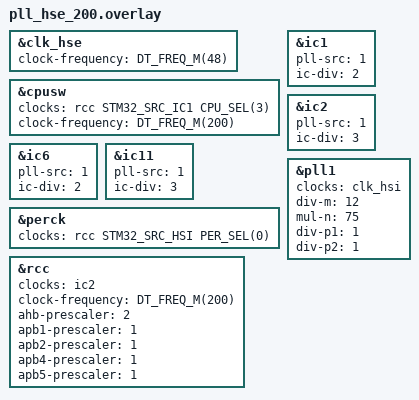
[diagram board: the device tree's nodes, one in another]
/*
 * Copyright (c) 2025 STMicroelectronics
 *
 * SPDX-License-Identifier: Apache-2.0
 */

/*
 * Warning: This overlay performs configuration from clean sheet.
 * It is assumed that it is applied after clear_clocks.overlay file.
 */

&clk_hse {
	clock-frequency = <DT_FREQ_M(48)>;
	status = "okay";
};

&cpusw {
	clocks = <&rcc STM32_SRC_IC1 CPU_SEL(3)>;
	clock-frequency = <DT_FREQ_M(200)>;
	status = "okay";
};

&ic1 {
	pll-src = <1>;
	ic-div = <2>;
	status = "okay";
};

&ic2 {
	pll-src = <1>;
	ic-div = <3>;
	status = "okay";
};

&ic6 {
	pll-src = <1>;
	ic-div = <2>;
	status = "okay";
};

&ic11 {
	pll-src = <1>;
	ic-div = <3>;
	status = "okay";
};

&perck {
	clocks = <&rcc STM32_SRC_HSI PER_SEL(0)>;
	status = "okay";
};

&pll1 {
	clocks = <&clk_hsi>;
	div-m = <12>;
	mul-n = <75>;
	div-p1 = <1>;
	div-p2 = <1>;
	status = "okay";
};

&rcc {
	/* ic2, ic6 & ic11 must all be enabled to set ic2 as SYSCLK */
	clocks = <&ic2>;
	clock-frequency = <DT_FREQ_M(200)>;
	ahb-prescaler = <2>;
	apb1-prescaler = <1>;
	apb2-prescaler = <1>;
	apb4-prescaler = <1>;
	apb5-prescaler = <1>;
};
